# LPC5410x register map
File version: 0.4
CPU: CM4 r0p0, little endian, no MPU, no FPU, 0x3 interrupt priority bits, 0x0 interrupts
Registers are 32-bit, read-write, reset 0x0 unless marked. A register's access mark holds for its fields unless they carry their own. Offsets are from the block's base; [hi:lo] are bit positions; {n}, {i} and the like mark numbered series; 'fields as' and 'values as' point back to an identical list.

## VFIFO — System FIFO for Serial Peripherals
Base 0x1C038000
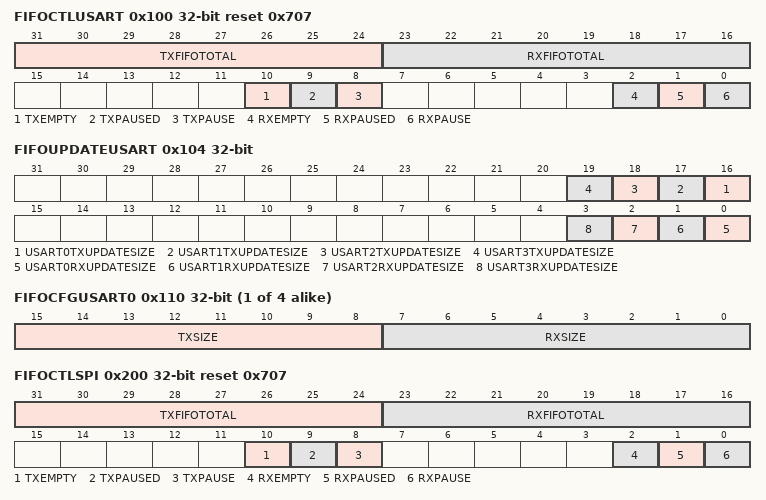
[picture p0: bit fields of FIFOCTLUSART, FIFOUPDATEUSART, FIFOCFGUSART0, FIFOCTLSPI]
0x100 FIFOCTLUSART reset 0x707 — USART FIFO global control register. These registers are byte, halfword, and word addressable.The upper 16 bits of these registers provide information about the System FIFO configuration, and are specific to each device type.
  [31:24] TXFIFOTOTAL — Reports the transmit FIFO space available for USARTs on this FIFO. The reset value is device specific.
  [23:16] RXFIFOTOTAL — Reports the receive FIFO space available for USARTs on this FIFO. The reset value is device specific.
  [10] TXEMPTY — All USART transmit FIFOs are empty.
  [9] TXPAUSED — All USART transmit FIFOs are paused.
  [8] TXPAUSE — Pause all USARTs transmit FIFO operations. This can be used to prepare the System FIFO to reconfigure FIFO allocations among the USART transmitters.
  [2] RXEMPTY — All USART receive FIFOs are empty.
  [1] RXPAUSED — All USART receive FIFOs are paused.
  [0] RXPAUSE — Pause all USARTs receive FIFO operations. This can be used to prepare the System FIFO to reconfigure FIFO allocations among the USART receivers.
0x104 FIFOUPDATEUSART wo reset not defined — USART FIFO global update register
  [n+16] USART{n}TXUPDATESIZE (n=0..3) — Writing 1 updates USART{n} Tx FIFO size to match the USART{n} TXSIZE. Must be done for all USARTs when any USART TXSIZE is changed.
  [n] USART{n}RXUPDATESIZE (n=0..3) — Writing 1 updates USART{n} Rx FIFO size to match the USART{n} RXSIZE. Must be done for all USARTs when any USART RXSIZE is changed.
{0x110+4i} FIFOCFGUSART{i} (i=0..3) — FIFO configuration register for USART0
  [15:8] TXSIZE — Configures the USART transmit FIFO size. A zero values provides no System FIFO service for the related USART transmitter.
  [7:0] RXSIZE — Configures the USART receive FIFO size. A zero values provides no System FIFO service for the related USART receiver.
0x200 FIFOCTLSPI reset 0x707 — SPI FIFO global control register. These registers are byte, halfword, and word addressable. The upper 16 bits of these registers provide information about the System FIFO configuration, and are specific to each device type.
  [31:24] TXFIFOTOTAL — Reports the transmit FIFO space available for SPIs on the System FIFO. The reset value is device specific.
  [23:16] RXFIFOTOTAL — Reports the receive FIFO space available for SPIs on the System FIFO. The reset value is device specific.
  [10] TXEMPTY — All SPI transmit FIFOs are empty.
  [9] TXPAUSED — All SPI transmit FIFOs are paused.
  [8] TXPAUSE — Pause all SPIs transmit FIFO operations. This can be used to prepare the System FIFO to reconfigure FIFO allocations among the SPI transmitters.
  [2] RXEMPTY — All SPI receive FIFOs are empty.
  [1] RXPAUSED — All SPI receive FIFOs are paused.
  [0] RXPAUSE — Pause all SPIs receive FIFO operations. This can be used to prepare the System FIFO to reconfigure FIFO allocations among the SPI receivers.
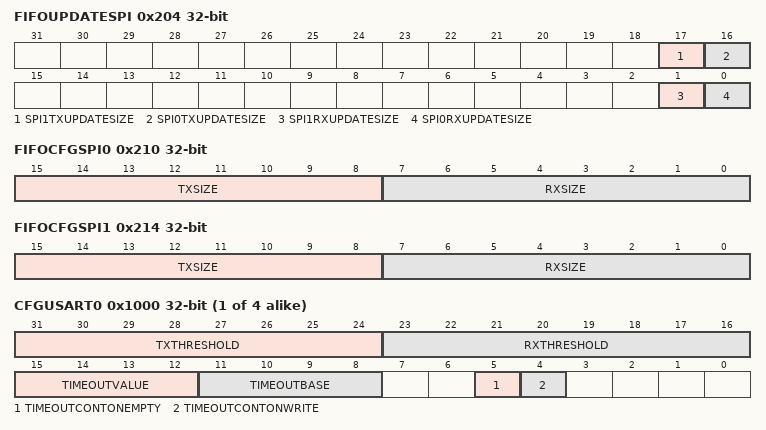
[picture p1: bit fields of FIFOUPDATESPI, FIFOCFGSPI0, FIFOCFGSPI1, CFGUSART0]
0x204 FIFOUPDATESPI wo reset not defined — SPI FIFO global update register
  [17] SPI1TXUPDATESIZE — Writing 1 updates SPI1 Tx FIFO size to match the SPI1 TXSIZE. Must be done for all SPIs when any SPI TXSIZE is changed.
  [16] SPI0TXUPDATESIZE — Writing 1 updates SPI0 Tx FIFO size to match the SPI0 TXSIZE. Must be done for all SPIs when any SPI TXSIZE is changed.
  [1] SPI1RXUPDATESIZE — Writing 1 updates SPI1 Rx FIFO size to match the SPI1 RXSIZE. Must be done for all SPIs when any SPI RXSIZE is changed.
  [0] SPI0RXUPDATESIZE — Writing 1 updates SPI0 Rx FIFO size to match the SPI0 RXSIZE. Must be done for all SPIs when any SPI RXSIZE is changed.
0x210 FIFOCFGSPI0 — FIFO configuration register for SPI0
  [15:8] TXSIZE — Configures the SPI transmit FIFO size. A zero values provides no System FIFO service for the related SPI transmitter.
  [7:0] RXSIZE — Configures the SPI receive FIFO size. A zero values provides no System FIFO service for the related SPI receiver.
0x214 FIFOCFGSPI1 — FIFO configuration register for SPI0
  fields as FIFOCFGSPI0
{0x1000+0x100*i} CFGUSART{i} (i=0..3) — USART0 configuration
  [31:24] TXTHRESHOLD — Transmit FIFO Threshold. The System FIFO indicates that the threshold has been reached when the number of free entries in the transmit FIFO is less than or equal to this value. For example, when TxThreshold = 0, the threshold is exceeded when there is at least one free entry in the transmit FIFO. An interrupt can be generated when the TxThreshold has been reached (see Section 24.5.10), but has no effect on DMA requests, which are generated whenever the transmit FIFO has any free entries.
  [23:16] RXTHRESHOLD — Receive FIFO Threshold. The System FIFO indicates that the threshold has been reached when the number of entries in the receive FIFO is greater than this value. For example, when RxThreshold = 0, the threshold is exceeded when there is at least one entry in the receive FIFO. An interrupt can be generated when the RxThreshold has been reached (see Section 24.5.10), but has no effect on DMA requests, which are generated whenever the receiver FIFO is not empty.
  [15:12] TIMEOUTVALUE — Specifies the maximum time value for timeout at the timer position identified by TimeoutBase. Minimum time TimeoutValue - 1. is See Section 24.5.7.1 below. TimeoutValue should not be 0 or 1 when timeout is enabled.
  [11:8] TIMEOUTBASE — Specifies the least significant timer bit to compare to TimeoutValue. See Section 24.5.7.1 below. Value can be 0 through 15.
  [5] TIMEOUTCONTONEMPTY — Timeout Continue On Empty. When 0, the timeout for the related peripheral is reset when the receive FIFO becomes empty. When 1, the timeout for the related peripheral is not reset when the receive FIFO becomes empty. This allows the timeout to be used to flag idle peripherals, and could potentially be used to indicate the end of a transmission of indeterminate length.
  [4] TIMEOUTCONTONWRITE — Timeout Continue On Write. When 0, the timeout for the related peripheral is reset every time data is transferred from the peripheral into the receive FIFO. When 1, the timeout for the related peripheral is not reset every time data is transferred into the receive FIFO. This allows the timeout to be applied to accumulated data, perhaps related to the FIFO threshold.
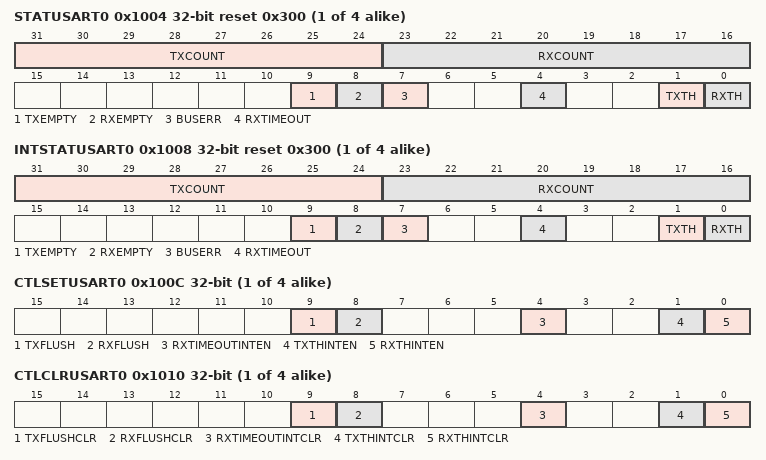
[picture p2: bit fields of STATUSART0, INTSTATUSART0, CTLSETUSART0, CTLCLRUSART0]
{0x1004+0x100*i} STATUSART{i} reset 0x300 (i=0..3) — USART0 status
  [31:24] TXCOUNT — Transmit FIFO Count. Indicates how many entries may be written to the transmit FIFO. 0 = FIFO full. This is a read-only field that is valid only when the TxFIFO is fully configured and enabled.
  [23:16] RXCOUNT — Receive FIFO Count. Indicates how many entries may be read from the receive FIFO. 0 = FIFO empty. This is a read-only field.
  [9] TXEMPTY — Transmit FIFO Empty. When 1, the transmit FIFO is currently empty. This is a read-only bit.
  [8] RXEMPTY — Receive FIFO Empty. When 1, the receive FIFO is currently empty. This is a read-only bit.
  [7] BUSERR — Bus Error. When 1, a bus error has occurred while processing data for USARTn. The bus error flag can be cleared by writing a 1 to this bit.
  [4] RXTIMEOUT — Receive FIFO Timeout. When 1, the receive FIFO has timed out, based on the timeout configuration in the CFGUSART register. The timeout condition can be cleared by writing a 1 to this bit, by enabling or disabling the timeout interrupt, or by writing a 1 to the timeout interrupt enable.
  [1] TXTH — Transmit FIFO Threshold. When 1, the transmit FIFO threshold has been reached. This is a read-only bit.
  [0] RXTH — Receive FIFO Threshold. When 1, the receive FIFO threshold has been reached. This is a read-only bit.
{0x1008+0x100*i} INTSTATUSART{i} ro reset 0x300 (i=0..3) — USART0 interrupt status
  [31:24] TXCOUNT — Transmit FIFO Available. This is simply a copy of the same field in the STATUSART register, included here so an ISR can read all needed status information in one read.
  [23:16] RXCOUNT — Receive FIFO Count. This is simply a copy of the same field in the STATUSART register, included here so an ISR can read all needed status information in one read.
  [9] TXEMPTY — Transmit FIFO Empty. This is simply a copy of the same bit in the STATUSART register.
  [8] RXEMPTY — Receive FIFO Empty. This is simply a copy of the same bit in the STATUSART register.
  [7] BUSERR — Bus Error. This is simply a copy of the same bit in the STATUSART register. The bus error interrupt is always enabled.
  [4] RXTIMEOUT — Receive Timeout. When 1, the receive FIFO has timed out, based on the timeout configuration in the CFGUSART register, and the related interrupt is enabled.
  [1] TXTH — Transmit FIFO Threshold. When 1, the transmit FIFO threshold has been reached, and the related interrupt is enabled.
  [0] RXTH — Receive FIFO Threshold. When 1, the receive FIFO threshold has been reached, and the related interrupt is enabled.
{0x100C+0x100*i} CTLSETUSART{i} (i=0..3) — USART0 control read and set register. A complete value may be read from this register. Writing a 1 to any implemented bit position causes that bit to be set.
  [9] TXFLUSH — Transmit FIFO flush. Writing a 1 to this bit forces the transmit FIFO to be empty.
  [8] RXFLUSH — Receive FIFO flush. Writing a 1 to this bit forces the receive FIFO to be empty.
  [4] RXTIMEOUTINTEN — Receive FIFO Timeout Interrupt Enable. When enabled, this also enables the timeout for this USART. Writing a 1 to this bit resets the USART timeout logic.
  [1] TXTHINTEN — Transmit FIFO Threshold Interrupt Enable.
  [0] RXTHINTEN — Receive FIFO Threshold Interrupt Enable.
{0x1010+0x100*i} CTLCLRUSART{i} wo reset not defined (i=0..3) — USART0 control clear register. Writing a 1 to any implemented bit position causes the corresponding bit in the related CTLSET register to be cleared.
  [9] TXFLUSHCLR — Transmit FIFO flush clear.
  [8] RXFLUSHCLR — Receive FIFO flush clear.
  [4] RXTIMEOUTINTCLR — Receive FIFO Time-out Interrupt clear.
  [1] TXTHINTCLR — Transmit FIFO Threshold Interrupt clear.
  [0] RXTHINTCLR — Receive FIFO Threshold Interrupt clear.
{0x1014+0x100*i} RXDATUSART{i} ro reset not defined (i=0..3) — USART0 received data
  [8:0] RXDAT — The UART Receiver Data register contains the next received character. The number of bits that are relevant depends on the UART configuration settings.
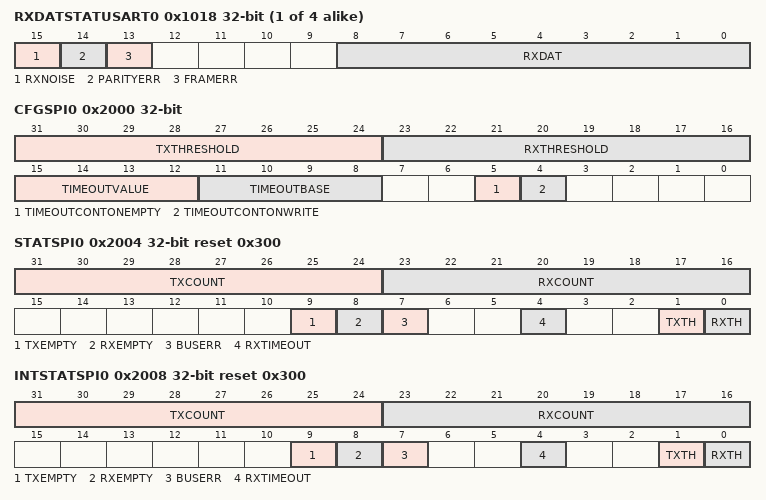
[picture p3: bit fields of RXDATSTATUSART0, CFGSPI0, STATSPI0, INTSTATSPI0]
{0x1018+0x100*i} RXDATSTATUSART{i} ro reset not defined (i=0..3) — USART0 received data with status
  [15] RXNOISE — Received Noise flag.
  [14] PARITYERR — Parity Error status flag. This bit is valid when there is a character to be read in the RXDAT register and reflects the status of that character. This bit will be set when a parity error is detected in a received character.
  [13] FRAMERR — Framing Error status flag. This bit is valid when there is a character to be read in the RXDAT register and reflects the status of that character. This bit will set when the character in RXDAT was received with a missing stop bit at the expected location. This could be an indication of a baud rate or configuration mismatch with the transmitting source.
  [8:0] RXDAT — The UART Receiver Data register contains the next received character. The number of bits that are relevant depends on the UART configuration settings.
{0x101C+0x100*i} TXDATUSART{i} wo (i=0..3) — USART0 transmit data
  [8:0] TXDAT — Writing to the UART Transmit Data Register causes the data to be transmitted as soon as the transmit shift register is available and the condition for transmitting data is met: TXDIS bit = 0.
0x2000 CFGSPI0 — SPI0 configuration
  [31:24] TXTHRESHOLD — Transmit FIFO Threshold. The System FIFO indicates that the threshold has been reached when the number of free entries in the transmit FIFO is less than or equal to this value. For example, when TxThreshold = 0, the threshold is exceeded when there is at least one free entry in the transmit FIFO. An interrupt can be generated when the TxThreshold has been reached, but has no effect on DMA requests, which are generated whenever the transmit FIFO has any free entries.
  [23:16] RXTHRESHOLD — Receive FIFO Threshold. The System FIFO indicates that the threshold has been reached when the number of entries in the receive FIFO is greater than this value. For example, when RxThreshold = 0, the threshold is exceeded when there is at least one entry in the receive FIFO. An interrupt can be generated when the RxThreshold has been reached, but has no effect on DMA requests, which are generated whenever the receiver FIFO is not empty.
  [15:12] TIMEOUTVALUE — Specifies the maximum time value for timeout at the timer position identified by TimeoutBase. Minimum time TimeoutValue - 1. TimeoutValue should not be 0 or 1 when timeout is enabled.
  [11:8] TIMEOUTBASE — Specifies the least significant timer bit to compare to TimeoutValue. Value can be 0 through 15.
  [5] TIMEOUTCONTONEMPTY — Timeout Continue On Empty. When 0, the timeout for the related peripheral is reset when the receive FIFO becomes empty. When 1, the timeout for the related peripheral is not reset when the receive FIFO becomes empty. This allows the timeout to be used to flag idle peripherals, and could potentially be used to indicate the end of a transmission of indeterminate length.
  [4] TIMEOUTCONTONWRITE — Timeout Continue On Write. When 0, the timeout for the related peripheral is reset every time data is transferred from the peripheral into the receive FIFO. When 1, the timeout for the related peripheral is not reset every time data is transferred into the receive FIFO. This allows the timeout to be applied to accumulated data, perhaps related to the FIFO threshold.
0x2004 STATSPI0 reset 0x300 — SPI0 status
  [31:24] TXCOUNT — Transmit FIFO Count. Indicates how many entries may be written to the transmit FIFO. 0 = FIFO full. This is a read-only field that is valid only when the TxFIFO is fully configured and enabled.
  [23:16] RXCOUNT — Receive FIFO Count. Indicates how many entries may be read from the receive FIFO. 0 = FIFO empty. This is a read-only field.
  [9] TXEMPTY — Transmit FIFO Empty. When 1, the transmit FIFO is currently empty. This is a read-only bit.
  [8] RXEMPTY — Receive FIFO Empty. When 1, the receive FIFO is currently empty. This is a read-only bit.
  [7] BUSERR — Bus Error. When 1, a bus error has occurred while processing data for SPI. The bus error flag can be cleared by writing a 1 to this bit.
  [4] RXTIMEOUT — Receive FIFO Timeout. When 1, the receive FIFO has timed out, based on the timeout configuration in the CFGSPI register. The timeout condition can be cleared by writing a 1 to this bit, by enabling or disabling the timeout interrupt, or by writing a 1 to the timeout interrupt enable.
  [1] TXTH — Transmit FIFO Threshold. When 1, the transmit FIFO threshold has been reached. This is a read-only bit.
  [0] RXTH — Receive FIFO Threshold. When 1, the receive FIFO threshold has been reached. This is a read-only bit.
0x2008 INTSTATSPI0 ro reset 0x300 — SPI0 interrupt status
  [31:24] TXCOUNT — Transmit FIFO Available. This is simply a copy of the same field in the STATSPI register, included here so an ISR can read all needed status information in one read.
  [23:16] RXCOUNT — Receive FIFO Count. This is simply a copy of the same field in the STATSPI register, included here so an ISR can read all needed status information in one read.
  [9] TXEMPTY — Transmit FIFO Empty. This is simply a copy of the same bit in the STATSPI register.
  [8] RXEMPTY — Receive FIFO Empty. This is simply a copy of the same bit in the STATSPI register.
  [7] BUSERR — Bus Error. This is simply a copy of the same bit in the STATSPI register. The bus error interrupt is always enabled.
  [4] RXTIMEOUT — Receive Timeout. When 1, the receive FIFO has timed out, based on the timeout configuration in the CFGSPI register, and the related interrupt is enabled.
  [1] TXTH — Transmit FIFO Threshold. When 1, the transmit FIFO threshold has been reached, and the related interrupt is enabled.
  [0] RXTH — Receive FIFO Threshold. When 1, the receive FIFO threshold has been reached, and the related interrupt is enabled.
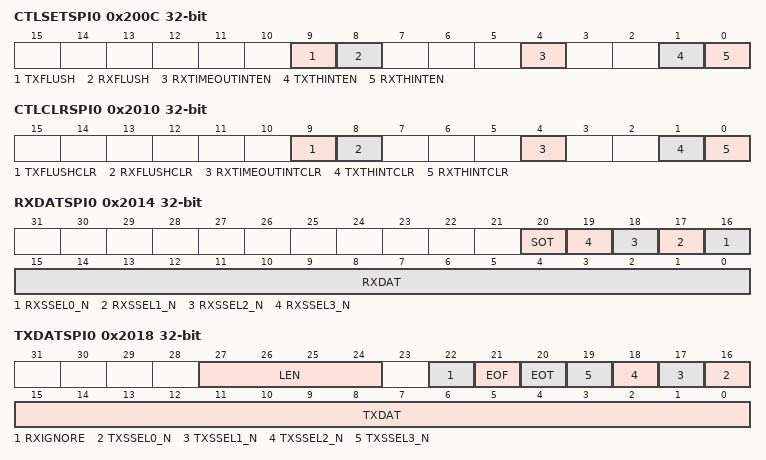
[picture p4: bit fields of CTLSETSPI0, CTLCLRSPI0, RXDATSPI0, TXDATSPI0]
0x200C CTLSETSPI0 — SPI0 control read and set register. A complete value may be read from this register. Writing a 1 to any implemented bit position causes that bit to be set.
  [9] TXFLUSH — Transmit FIFO flush. Writing a 1 to this bit forces the transmit FIFO to be empty.
  [8] RXFLUSH — Receive FIFO flush. Writing a 1 to this bit forces the receive FIFO to be empty.
  [4] RXTIMEOUTINTEN — Receive FIFO Timeout Interrupt Enable. When enabled, this also enables the timeout for this SPI. Writing a 1 to this bit resets the SPI timeout logic.
  [1] TXTHINTEN — Transmit FIFO Threshold Interrupt Enable.
  [0] RXTHINTEN — Receive FIFO Threshold Interrupt Enable.
0x2010 CTLCLRSPI0 wo reset not defined — SPI0 control clear register. Writing a 1 to any implemented bit position causes the corresponding bit in the related CTLSET register to be cleared.
  [9] TXFLUSHCLR — Transmit FIFO flush clear.
  [8] RXFLUSHCLR — Receive FIFO flush clear. do the clear bits 8 and 9 do anything?
  [4] RXTIMEOUTINTCLR — Receive FIFO Timeout Interrupt clear.
  [1] TXTHINTCLR — Transmit FIFO Threshold Interrupt clear.
  [0] RXTHINTCLR — Receive FIFO Threshold Interrupt clear.
0x2014 RXDATSPI0 ro reset not defined — SPI0 received data. These registers are half word addressable.
  [20] SOT — Start of Transfer flag. This flag will be 1 if this is the first data after the SSELs went from deasserted to asserted (i.e., any previous transfer has ended). This information can be used to identify the first piece of data in cases where the transfer length is greater than 16 bit.
  [n+16] RXSSEL{n}_N (n=0..3) — Slave Select for receive. This field allows the state of the SSEL{n} pin to be saved along with received data. The value will reflect the SSEL{n} pin for both master and slave operation. A zero indicates that a slave select is active. The actual polarity of each slave select pin is configured by the related SPOL bit in CFG.
  [15:0] RXDAT — Receiver Data. This contains the next piece of received data. The number of bits that are used depends on the LEN setting in TXCTL / TXDATCTL.
0x2018 TXDATSPI0 wo reset not defined — SPI0 transmit data. These registers are half word addressable.
  [27:24] LEN — Data Length. Specifies the data length from 1 to 16 bits. Note that transfer lengths greater than 16 bits are supported by implementing multiple sequential data transmits. 0x0 = Data transfer is 1 bit in length. 0x1 = Data transfer is 2 bits in length. 0x2 = Data transfer is 3 bits in length. ... 0xF = Data transfer is 16 bits in length.
  [22] RXIGNORE — Receive Ignore. This allows data to be transmitted using the SPI without the need to read unneeded data from the receiver to simplify the transmit process and can be used with the DMA.
    0=READ_RECEIVED_DATA (Read received data. Received data must be read in order to allow transmission to progress. In slave mode, an overrun error will occur if received data is not read before new data is received.); 1=IGNORE_RECEIVED_DATA (Ignore received data. Received data is ignored, allowing transmission without reading unneeded received data. No receiver flags are generated.)
  [21] EOF — End of Frame. Between frames, a delay may be inserted, as defined by the FRAME_DELAY value in the DLY register. The end of a frame may not be particularly meaningful if the FRAME_DELAY value = 0. This control can be used as part of the support for frame lengths greater than 16 bits.
    0=DATA_NOT_EOF (Data not EOF. This piece of data transmitted is not treated as the end of a frame.); 1=DATA_EOF (Data EOF. This piece of data is treated as the end of a frame, causing the FRAME_DELAY time to be inserted before subsequent data is transmitted.)
  [20] EOT — End of Transfer. The asserted SSEL will be deasserted at the end of a transfer, and remain so for at least the time specified by the Transfer_delay value in the DLY register.
    0=NOT_DEASSERTED (Not deasserted. SSEL not deasserted. This piece of data is not treated as the end of a transfer. SSEL will not be deasserted at the end of this data.); 1=DEASSERTED (Deasserted. SSEL deasserted. This piece of data is treated as the end of a transfer. SSEL will be deasserted at the end of this piece of data.)
  [n+16] TXSSEL{n}_N (n=0..3) — Transmit Slave Select. This field asserts SSEL{n} in master mode. The output on the pin is active LOW by default. The active state of the SSEL{n} pin is configured by bits in the CFG register.
    0=ASSERTED (Asserted. SSEL{n} asserted.); 1=NOT_ASSERTED (Not asserted. SSEL{n} not asserted.)
  [15:0] TXDAT — Transmit Data. This field provides from 1 to 16 bits of data to be transmitted.
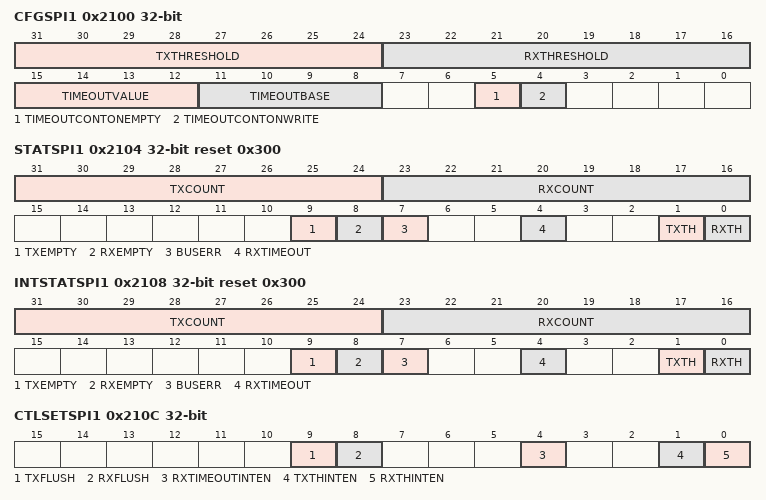
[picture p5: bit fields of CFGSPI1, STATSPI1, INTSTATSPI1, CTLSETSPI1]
0x2100 CFGSPI1 — SPI0 configuration
  fields as CFGSPI0
0x2104 STATSPI1 reset 0x300 — SPI0 status
  fields as STATSPI0
0x2108 INTSTATSPI1 ro reset 0x300 — SPI0 interrupt status
  fields as INTSTATSPI0
0x210C CTLSETSPI1 — SPI0 control read and set register. A complete value may be read from this register. Writing a 1 to any implemented bit position causes that bit to be set.
  fields as CTLSETSPI0
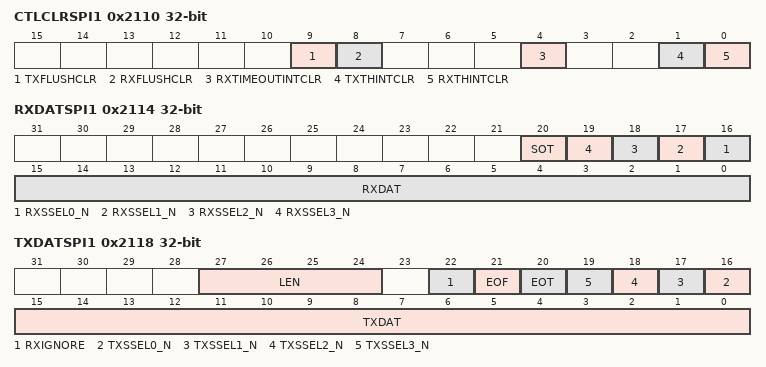
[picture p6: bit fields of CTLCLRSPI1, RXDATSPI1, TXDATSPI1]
0x2110 CTLCLRSPI1 wo reset not defined — SPI0 control clear register. Writing a 1 to any implemented bit position causes the corresponding bit in the related CTLSET register to be cleared.
  fields as CTLCLRSPI0
0x2114 RXDATSPI1 ro reset not defined — SPI0 received data. These registers are half word addressable.
  fields as RXDATSPI0
0x2118 TXDATSPI1 wo reset not defined — SPI0 transmit data. These registers are half word addressable.
  fields as TXDATSPI0
